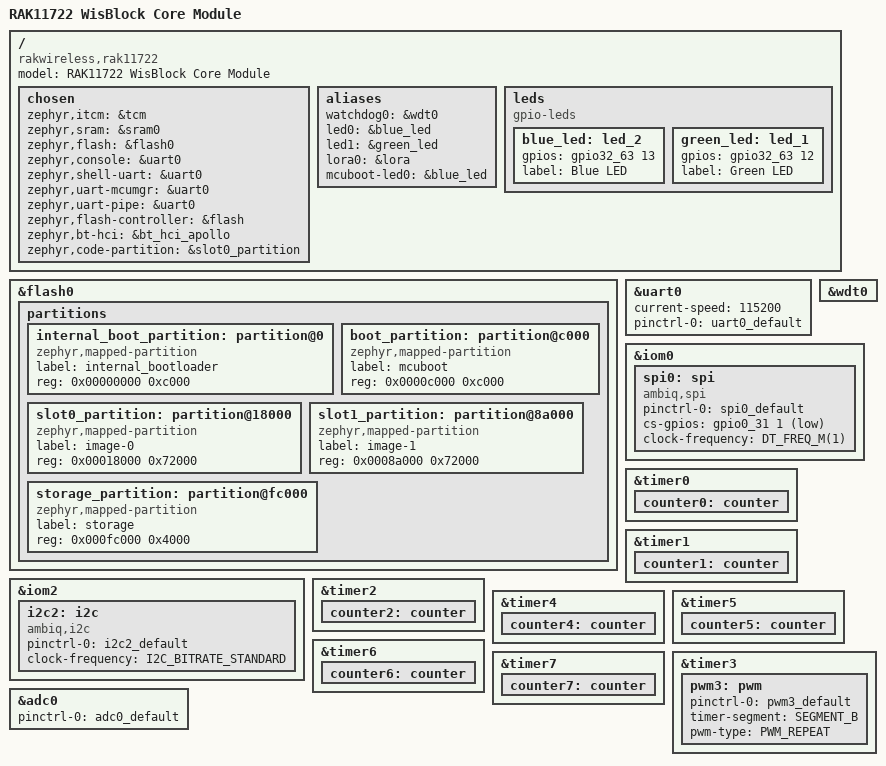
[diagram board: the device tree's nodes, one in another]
/*
 * Copyright (c) 2024 RAKwireless Technology Co., Ltd. <www.rakwireless.com>
 * Sercan Erat <sercanerat@gmail.com>
 * SPDX-License-Identifier: Apache-2.0
 */

/dts-v1/;
#include <rakwireless/rak11720.dtsi>
#include "rak11722-pinctrl.dtsi"
#include <zephyr/dt-bindings/input/input-event-codes.h>

/ {
	model = "RAK11722 WisBlock Core Module";
	compatible = "rakwireless,rak11722";

	chosen {
		zephyr,itcm = &tcm;
		zephyr,sram = &sram0;
		zephyr,flash = &flash0;
		zephyr,console = &uart0;
		zephyr,shell-uart = &uart0;
		zephyr,uart-mcumgr = &uart0;
		zephyr,uart-pipe = &uart0;
		zephyr,flash-controller = &flash;
		zephyr,bt-hci = &bt_hci_apollo;
		zephyr,code-partition = &slot0_partition;
	};

	aliases {
		watchdog0 = &wdt0;
		led0 = &blue_led;
		led1 = &green_led;
		lora0 = &lora;
		mcuboot-led0 = &blue_led;
	};

	leds {
		compatible = "gpio-leds";

		blue_led: led_2 {
			gpios = <&gpio32_63 13 GPIO_ACTIVE_HIGH>;
			label = "Blue LED";
		};

		green_led: led_1 {
			gpios = <&gpio32_63 12 GPIO_ACTIVE_HIGH>;
			label = "Green LED";
		};
	};
};

&flash0 {
	partitions {
		ranges;
		#address-cells = <1>;
		#size-cells = <1>;

		internal_boot_partition: partition@0 {
			compatible = "zephyr,mapped-partition";
			label = "internal_bootloader";
			reg = <0x00000000 0xc000>;
		};

		boot_partition: partition@c000 {
			compatible = "zephyr,mapped-partition";
			label = "mcuboot";
			reg = <0x0000c000 0xc000>;
		};

		slot0_partition: partition@18000 {
			compatible = "zephyr,mapped-partition";
			label = "image-0";
			reg = <0x00018000 0x72000>;
		};

		slot1_partition: partition@8a000 {
			compatible = "zephyr,mapped-partition";
			label = "image-1";
			reg = <0x0008a000 0x72000>;
		};

		storage_partition: partition@fc000 {
			compatible = "zephyr,mapped-partition";
			label = "storage";
			reg = <0x000fc000 0x4000>;
		};
	};
};

&uart0 {
	current-speed = <115200>;
	pinctrl-0 = <&uart0_default>;
	pinctrl-names = "default";
	status = "okay";
};

&wdt0 {
	status = "okay";
};

&iom2 {
	i2c2: i2c {
		compatible = "ambiq,i2c";
		pinctrl-0 = <&i2c2_default>;
		pinctrl-names = "default";
		clock-frequency = <I2C_BITRATE_STANDARD>;
		status = "okay";
	};
};

&iom0 {
	spi0: spi {
		compatible = "ambiq,spi";
		pinctrl-0 = <&spi0_default>;
		pinctrl-names = "default";
		cs-gpios = <&gpio0_31 1 GPIO_ACTIVE_LOW>;
		clock-frequency = <DT_FREQ_M(1)>;
		status = "okay";
	};
};

&timer0 {
	counter0: counter {
		status = "okay";
	};
};

&timer1 {
	counter1: counter {
		status = "okay";
	};
};

&timer2 {
	counter2: counter {
		status = "okay";
	};
};

&timer4 {
	counter4: counter {
		status = "okay";
	};
};

&timer5 {
	counter5: counter {
		status = "okay";
	};
};

&timer6 {
	counter6: counter {
		status = "okay";
	};
};

&timer7 {
	counter7: counter {
		status = "okay";
	};
};

&timer3 {
	pwm3: pwm {
		pinctrl-0 = <&pwm3_default>;
		pinctrl-names = "default";
		timer-segment = "SEGMENT_B";
		pwm-type = "PWM_REPEAT";
	};
};

&adc0 {
	pinctrl-0 = <&adc0_default>;
	pinctrl-names = "default";
	status = "okay";
};

#include "wisblock.dtsi"
